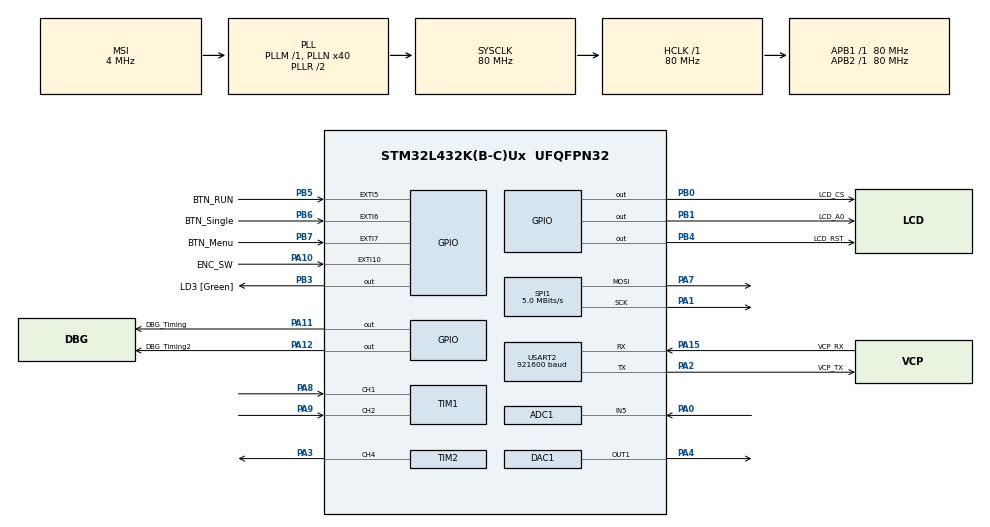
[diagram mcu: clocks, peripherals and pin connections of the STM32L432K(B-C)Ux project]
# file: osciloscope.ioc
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ADC1.ClockPrescaler=ADC_CLOCK_SYNC_PCLK_DIV1
ADC1.Channel-0\#ChannelRegularConversion=ADC_CHANNEL_5
ADC1.DMAContinuousRequests=ENABLE
ADC1.ExternalTrigConv=ADC_EXTERNALTRIG_T6_TRGO
ADC1.NbrOfConversionFlag=1
ADC1.Overrun=ADC_OVR_DATA_OVERWRITTEN
ADC1.OffsetNumber-0\#ChannelRegularConversion=ADC_OFFSET_NONE
ADC1.Rank-0\#ChannelRegularConversion=1
ADC1.SamplingTime-0\#ChannelRegularConversion=ADC_SAMPLETIME_2CYCLES_5
ADC1.master=1
DAC1.DAC_Trigger-DAC_OUT1=DAC_TRIGGER_T7_TRGO
Dma.ADC1.0.Direction=DMA_PERIPH_TO_MEMORY
Dma.ADC1.0.Instance=DMA1_Channel1
Dma.ADC1.0.MemDataAlignment=DMA_MDATAALIGN_HALFWORD
Dma.ADC1.0.MemInc=DMA_MINC_ENABLE
Dma.ADC1.0.Mode=DMA_CIRCULAR
Dma.ADC1.0.PeriphDataAlignment=DMA_PDATAALIGN_HALFWORD
Dma.ADC1.0.PeriphInc=DMA_PINC_DISABLE
Dma.ADC1.0.Priority=DMA_PRIORITY_VERY_HIGH
Dma.DAC_CH1.3.Direction=DMA_MEMORY_TO_PERIPH
Dma.DAC_CH1.3.Instance=DMA2_Channel4
Dma.DAC_CH1.3.MemDataAlignment=DMA_MDATAALIGN_HALFWORD
Dma.DAC_CH1.3.MemInc=DMA_MINC_ENABLE
Dma.DAC_CH1.3.Mode=DMA_CIRCULAR
Dma.DAC_CH1.3.PeriphDataAlignment=DMA_PDATAALIGN_HALFWORD
Dma.DAC_CH1.3.PeriphInc=DMA_PINC_DISABLE
Dma.DAC_CH1.3.Priority=DMA_PRIORITY_LOW
Dma.Request0=ADC1
Dma.Request1=USART2_RX
Dma.Request2=USART2_TX
Dma.Request3=DAC_CH1
Dma.Request4=SPI1_TX
Dma.SPI1_TX.4.Direction=DMA_MEMORY_TO_PERIPH
Dma.SPI1_TX.4.Instance=DMA1_Channel3
Dma.SPI1_TX.4.MemDataAlignment=DMA_MDATAALIGN_BYTE
Dma.SPI1_TX.4.MemInc=DMA_MINC_ENABLE
Dma.SPI1_TX.4.Mode=DMA_NORMAL
Dma.SPI1_TX.4.PeriphDataAlignment=DMA_PDATAALIGN_BYTE
Dma.SPI1_TX.4.PeriphInc=DMA_PINC_DISABLE
Dma.SPI1_TX.4.Priority=DMA_PRIORITY_MEDIUM
Dma.USART2_RX.1.Direction=DMA_PERIPH_TO_MEMORY
Dma.USART2_RX.1.Instance=DMA1_Channel6
Dma.USART2_RX.1.MemDataAlignment=DMA_MDATAALIGN_BYTE
Dma.USART2_RX.1.MemInc=DMA_MINC_ENABLE
Dma.USART2_RX.1.Mode=DMA_CIRCULAR
Dma.USART2_RX.1.PeriphDataAlignment=DMA_PDATAALIGN_BYTE
Dma.USART2_RX.1.PeriphInc=DMA_PINC_DISABLE
Dma.USART2_RX.1.Priority=DMA_PRIORITY_MEDIUM
Dma.USART2_TX.2.Direction=DMA_MEMORY_TO_PERIPH
Dma.USART2_TX.2.Instance=DMA1_Channel7
Dma.USART2_TX.2.MemDataAlignment=DMA_MDATAALIGN_BYTE
Dma.USART2_TX.2.MemInc=DMA_MINC_ENABLE
Dma.USART2_TX.2.Mode=DMA_NORMAL
Dma.USART2_TX.2.PeriphDataAlignment=DMA_PDATAALIGN_BYTE
Dma.USART2_TX.2.PeriphInc=DMA_PINC_DISABLE
Dma.USART2_TX.2.Priority=DMA_PRIORITY_LOW
IWDG.Prescaler=IWDG_PRESCALER_16
IWDG.Reload=1000
IWDG.Window=4095
Mcu.Family=STM32L4
Mcu.Name=STM32L432K(B-C)Ux
Mcu.Package=UFQFPN32
NVIC.ADC1_IRQn=true\:1\:0\:true\:false\:true\:true\:true\:true
NVIC.DMA1_Channel1_IRQn=true\:0\:0\:false\:false\:true\:false\:true\:true
NVIC.DMA1_Channel3_IRQn=true\:3\:0\:true\:false\:true\:false\:true\:true
NVIC.DMA1_Channel6_IRQn=true\:2\:0\:true\:false\:true\:false\:true\:true
NVIC.DMA1_Channel7_IRQn=true\:2\:0\:true\:false\:true\:false\:true\:true
NVIC.DMA2_Channel4_IRQn=true\:4\:0\:true\:false\:true\:false\:true\:true
NVIC.EXTI15_10_IRQn=true\:5\:0\:true\:false\:true\:true\:true\:true
NVIC.EXTI9_5_IRQn=true\:5\:0\:true\:false\:true\:true\:true\:true
NVIC.PriorityGroup=NVIC_PRIORITYGROUP_4
NVIC.SPI1_IRQn=true\:3\:0\:true\:false\:true\:true\:true\:true
NVIC.USART2_IRQn=true\:2\:0\:true\:false\:true\:true\:true\:true
PA0.Signal=ADCx_IN5
PA1.GPIO_Speed=GPIO_SPEED_FREQ_MEDIUM
PA1.Mode=TX_Only_Simplex_Unidirect_Master
PA1.Signal=SPI1_SCK
PA10.GPIO_ModeDefaultEXTI=GPIO_MODE_IT_FALLING
PA10.GPIO_Label=ENC_SW
PA10.GPIO_PuPd=GPIO_PULLUP
PA10.Signal=GPXTI10
PA11.GPIO_Label=DBG_Timing
PA11.GPIO_Speed=GPIO_SPEED_FREQ_HIGH
PA11.Signal=GPIO_Output
PA12.GPIO_Label=DBG_Timing2
PA12.GPIO_Speed=GPIO_SPEED_FREQ_HIGH
PA12.Signal=GPIO_Output
PA13\ (JTMS-SWDIO).GPIO_Label=SWDIO
PA13\ (JTMS-SWDIO).Mode=Serial_Wire
PA13\ (JTMS-SWDIO).Signal=SYS_JTMS-SWDIO
PA14\ (JTCK-SWCLK).GPIO_Label=SWCLK
PA14\ (JTCK-SWCLK).Mode=Serial_Wire
PA14\ (JTCK-SWCLK).Signal=SYS_JTCK-SWCLK
PA15\ (JTDI).GPIO_Label=VCP_RX
PA15\ (JTDI).Mode=Asynchronous
PA15\ (JTDI).Signal=USART2_RX
PA2.GPIO_Label=VCP_TX
PA2.Mode=Asynchronous
PA2.Signal=USART2_TX
PA3.Signal=S_TIM2_CH4
PA4.Signal=COMP_DAC11_group
PA7.GPIO_Speed=GPIO_SPEED_FREQ_MEDIUM
PA7.Mode=TX_Only_Simplex_Unidirect_Master
PA7.Signal=SPI1_MOSI
PA8.GPIO_PuPd=GPIO_PULLUP
PA8.Signal=S_TIM1_CH1
PA9.GPIO_PuPd=GPIO_PULLUP
PA9.Signal=S_TIM1_CH2
PB0.GPIO_Label=LCD_CS
PB0.GPIO_PuPd=GPIO_NOPULL
PB0.GPIO_Speed=GPIO_SPEED_FREQ_MEDIUM
PB0.PinState=GPIO_PIN_SET
PB0.Signal=GPIO_Output
PB1.GPIO_Label=LCD_A0
PB1.GPIO_Speed=GPIO_SPEED_FREQ_MEDIUM
PB1.Signal=GPIO_Output
PB3\ (JTDO-TRACESWO).GPIO_Label=LD3 [Green]
PB3\ (JTDO-TRACESWO).Signal=GPIO_Output
PB4\ (NJTRST).GPIO_Label=LCD_RST
PB4\ (NJTRST).Signal=GPIO_Output
PB5.GPIO_ModeDefaultEXTI=GPIO_MODE_IT_FALLING
PB5.GPIO_Label=BTN_RUN
PB5.GPIO_PuPd=GPIO_PULLUP
PB5.Signal=GPXTI5
PB6.GPIO_ModeDefaultEXTI=GPIO_MODE_IT_FALLING
PB6.GPIO_Label=BTN_Single
PB6.GPIO_PuPd=GPIO_PULLUP
PB6.Signal=GPXTI6
PB7.GPIO_ModeDefaultEXTI=GPIO_MODE_IT_FALLING
PB7.GPIO_Label=BTN_Menu
PB7.GPIO_PuPd=GPIO_PULLUP
PB7.Signal=GPXTI7
PC14-OSC32_IN\ (PC14).Mode=LSE-External-Oscillator
PC14-OSC32_IN\ (PC14).Signal=RCC_OSC32_IN
PC15-OSC32_OUT\ (PC15).Mode=LSE-External-Oscillator
PC15-OSC32_OUT\ (PC15).Signal=RCC_OSC32_OUT
ProjectManager.HeapSize=0x200
ProjectManager.StackSize=0x1000
ProjectManager.TargetToolchain=STM32CubeIDE
RCC.ADCCLockSelection=RCC_ADCCLKSOURCE_SYSCLK
RCC.ADCFreq_Value=80000000
RCC.AHBFreq_Value=80000000
RCC.APB1Freq_Value=80000000
RCC.APB1TimFreq_Value=80000000
RCC.APB2Freq_Value=80000000
RCC.APB2TimFreq_Value=80000000
RCC.CortexFreq_Value=80000000
RCC.HCLKFreq_Value=80000000
RCC.HSE_VALUE=8000000
RCC.HSI16_VALUE=16000000
RCC.HSI48_VALUE=48000000
RCC.HSI_VALUE=16000000
RCC.MSI_VALUE=4000000
RCC.PLLMUL=RCC_PLLMUL_4
RCC.PLLN=40
RCC.SYSCLKFreq_VALUE=80000000
RCC.SYSCLKSource=RCC_SYSCLKSOURCE_PLLCLK
RCC.VCOOutputFreq_Value=160000000
SH.ADCx_IN5.0=ADC1_IN5,IN5-Single-Ended
SH.COMP_DAC11_group.0=DAC1_OUT1,DAC_OUT1
SH.S_TIM1_CH1.0=TIM1_CH1,Encoder_Interface
SH.S_TIM1_CH2.0=TIM1_CH2,Encoder_Interface
SH.S_TIM2_CH4.0=TIM2_CH4,PWM Generation4 CH4
SPI1.BaudRatePrescaler=SPI_BAUDRATEPRESCALER_16
SPI1.CalculateBaudRate=5.0 MBits/s
SPI1.DataSize=SPI_DATASIZE_8BIT
SPI1.Direction=SPI_DIRECTION_2LINES
SPI1.NSSPMode=SPI_NSS_PULSE_DISABLE
SPI1.Mode=SPI_MODE_MASTER
SPI1.VirtualType=VM_MASTER
TIM1.EncoderMode=TIM_ENCODERMODE_TI12
TIM1.IC1Filter=10
TIM1.IC2Filter=10
TIM2.AutoReloadPreload=TIM_AUTORELOAD_PRELOAD_ENABLE
TIM2.Channel-PWM\ Generation4\ CH4=TIM_CHANNEL_4
TIM2.Period=4000-1
TIM2.Pulse-PWM\ Generation4\ CH4=2000
TIM6.AutoReloadPreload=TIM_AUTORELOAD_PRELOAD_ENABLE
TIM6.Period=17
TIM6.TIM_MasterOutputTrigger=TIM_TRGO_UPDATE
TIM7.AutoReloadPreload=TIM_AUTORELOAD_PRELOAD_ENABLE
TIM7.Period=800-1
TIM7.TIM_MasterOutputTrigger=TIM_TRGO_UPDATE
USART2.BaudRate=921600
USART2.DMADisableonRxErrorParam=ADVFEATURE_DMA_DISABLEONRXERROR
USART2.OverrunDisableParam=ADVFEATURE_OVERRUN_DISABLE
USART2.VirtualMode-Asynchronous=VM_ASYNC
VP_CRC_VS_CRC.Mode=CRC_Activate
VP_IWDG_VS_IWDG.Mode=IWDG_Activate
VP_TIM2_VS_ClockSourceINT.Mode=Internal
VP_TIM6_VS_ClockSourceINT.Mode=Enable_Timer
VP_TIM7_VS_ClockSourceINT.Mode=Enable_Timer
board=NUCLEO-L432KC

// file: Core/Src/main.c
/* USER CODE BEGIN Header */
/**
  ******************************************************************************
  * @file           : main.c
  * @brief          : Main program body
  ******************************************************************************
  * @attention
  *
  * Copyright (c) 2026 STMicroelectronics.
  * All rights reserved.
  *
  * This software is licensed under terms that can be found in the LICENSE file
  * in the root directory of this software component.
  * If no LICENSE file comes with this software, it is provided AS-IS.
  *
  ******************************************************************************
  */
/* USER CODE END Header */
#include "main.h"
#include "adc.h"
#include "crc.h"
#include "dac.h"
#include "dma.h"
#include "spi.h"
#include "tim.h"
#include "usart.h"
#include "gpio.h"

/* USER CODE BEGIN Includes */
#include "../App/app.h"
/* USER CODE END Includes */

void SystemClock_Config(void);

int main(void)
{

  /* MCU Configuration--------------------------------------------------------*/

  /* Reset of all peripherals, Initializes the Flash interface and the Systick. */
  HAL_Init();

  /* Configure the system clock */
  SystemClock_Config();

  /* Initialize all configured peripherals */
  MX_GPIO_Init();
  MX_DMA_Init();
  MX_USART2_UART_Init();
  MX_ADC1_Init();
  MX_SPI1_Init();
  MX_TIM6_Init();
  MX_DAC1_Init();
  MX_TIM1_Init();
  MX_TIM2_Init();
  MX_TIM7_Init();
  MX_CRC_Init();
  /* USER CODE BEGIN 2 */
  /* All application start-up (ADC calibration, VREFINT, DMA streams, LCD,
   * PC link, watchdog) lives in Core/App/app.c so that CubeMX regenerations
   * never touch it. */
  app_init();
  /* USER CODE END 2 */

  /* Infinite loop */
  while (1)
  {

    /* USER CODE BEGIN 3 */
    app_loop_once();
  }
  /* USER CODE END 3 */
}

void SystemClock_Config(void)
{
  RCC_OscInitTypeDef RCC_OscInitStruct = {0};
  RCC_ClkInitTypeDef RCC_ClkInitStruct = {0};

  /** Configure the main internal regulator output voltage
  */
  if (HAL_PWREx_ControlVoltageScaling(PWR_REGULATOR_VOLTAGE_SCALE1) != HAL_OK)
  {
    Error_Handler();
  }

  /** Configure LSE Drive Capability
  */
  HAL_PWR_EnableBkUpAccess();
  __HAL_RCC_LSEDRIVE_CONFIG(RCC_LSEDRIVE_LOW);

  /** Initializes the RCC Oscillators according to the specified parameters
  * in the RCC_OscInitTypeDef structure.
  */
  RCC_OscInitStruct.OscillatorType = RCC_OSCILLATORTYPE_LSI|RCC_OSCILLATORTYPE_LSE
                              |RCC_OSCILLATORTYPE_MSI;
  RCC_OscInitStruct.LSEState = RCC_LSE_ON;
  RCC_OscInitStruct.LSIState = RCC_LSI_ON;
  RCC_OscInitStruct.MSIState = RCC_MSI_ON;
  RCC_OscInitStruct.MSICalibrationValue = 0;
  RCC_OscInitStruct.MSIClockRange = RCC_MSIRANGE_6;
  RCC_OscInitStruct.PLL.PLLState = RCC_PLL_ON;
  RCC_OscInitStruct.PLL.PLLSource = RCC_PLLSOURCE_MSI;
  RCC_OscInitStruct.PLL.PLLM = 1;
  RCC_OscInitStruct.PLL.PLLN = 40;
  RCC_OscInitStruct.PLL.PLLP = RCC_PLLP_DIV7;
  RCC_OscInitStruct.PLL.PLLQ = RCC_PLLQ_DIV2;
  RCC_OscInitStruct.PLL.PLLR = RCC_PLLR_DIV2;
  if (HAL_RCC_OscConfig(&RCC_OscInitStruct) != HAL_OK)
  {
    Error_Handler();
  }

  /** Initializes the CPU, AHB and APB buses clocks
  */
  RCC_ClkInitStruct.ClockType = RCC_CLOCKTYPE_HCLK|RCC_CLOCKTYPE_SYSCLK
                              |RCC_CLOCKTYPE_PCLK1|RCC_CLOCKTYPE_PCLK2;
  RCC_ClkInitStruct.SYSCLKSource = RCC_SYSCLKSOURCE_PLLCLK;
  RCC_ClkInitStruct.AHBCLKDivider = RCC_SYSCLK_DIV1;
  RCC_ClkInitStruct.APB1CLKDivider = RCC_HCLK_DIV1;
  RCC_ClkInitStruct.APB2CLKDivider = RCC_HCLK_DIV1;

  if (HAL_RCC_ClockConfig(&RCC_ClkInitStruct, FLASH_LATENCY_4) != HAL_OK)
  {
    Error_Handler();
  }

  /** Enable MSI Auto calibration
  */
  HAL_RCCEx_EnableMSIPLLMode();
}

void Error_Handler(void)
{
  __disable_irq();
  while (1)
  {
  }
}
